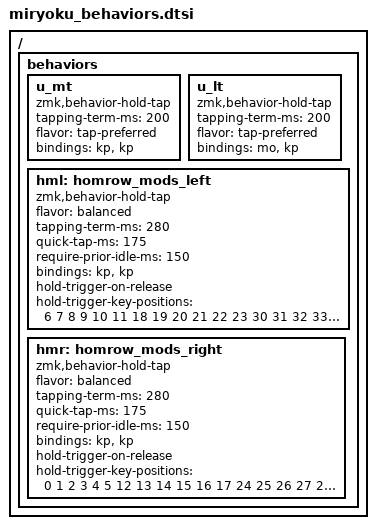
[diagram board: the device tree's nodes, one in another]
/ {
  behaviors {
    /* Standard Miryoku tap-preferred behaviors */
    u_mt: u_mt {
      compatible = "zmk,behavior-hold-tap";
      #binding-cells = <2>;
      tapping-term-ms = <200>;
      flavor = "tap-preferred";
      bindings = <&kp>, <&kp>;
    };

    u_lt: u_lt {
      compatible = "zmk,behavior-hold-tap";
      #binding-cells = <2>;
      tapping-term-ms = <200>;
      flavor = "tap-preferred";
      bindings = <&mo>, <&kp>;
    };

    /* Urob's Timeless HRMs - Left Hand */
    hml: homrow_mods_left {
        compatible = "zmk,behavior-hold-tap";
        #binding-cells = <2>;
        flavor = "balanced";
        tapping-term-ms = <280>;
        quick-tap-ms = <175>;
        require-prior-idle-ms = <150>;
        bindings = <&kp>, <&kp>;
        hold-trigger-on-release;
        /* Trigger list: Right hand alphas + Right thumbs */
        hold-trigger-key-positions = <6 7 8 9 10 11 18 19 20 21 22 23 30 31 32 33 34 35 39 40 41>; 
    };
    
    /* Urob's Timeless HRMs - Right Hand */
    hmr: homrow_mods_right {
        compatible = "zmk,behavior-hold-tap";
        #binding-cells = <2>;
        flavor = "balanced";
        tapping-term-ms = <280>;
        quick-tap-ms = <175>;
        require-prior-idle-ms = <150>;
        bindings = <&kp>, <&kp>;
        hold-trigger-on-release;
        /* Trigger list: Left hand alphas + Left thumbs */
        hold-trigger-key-positions = <0 1 2 3 4 5 12 13 14 15 16 17 24 25 26 27 28 29 36 37 38>;
    };
  };
};
